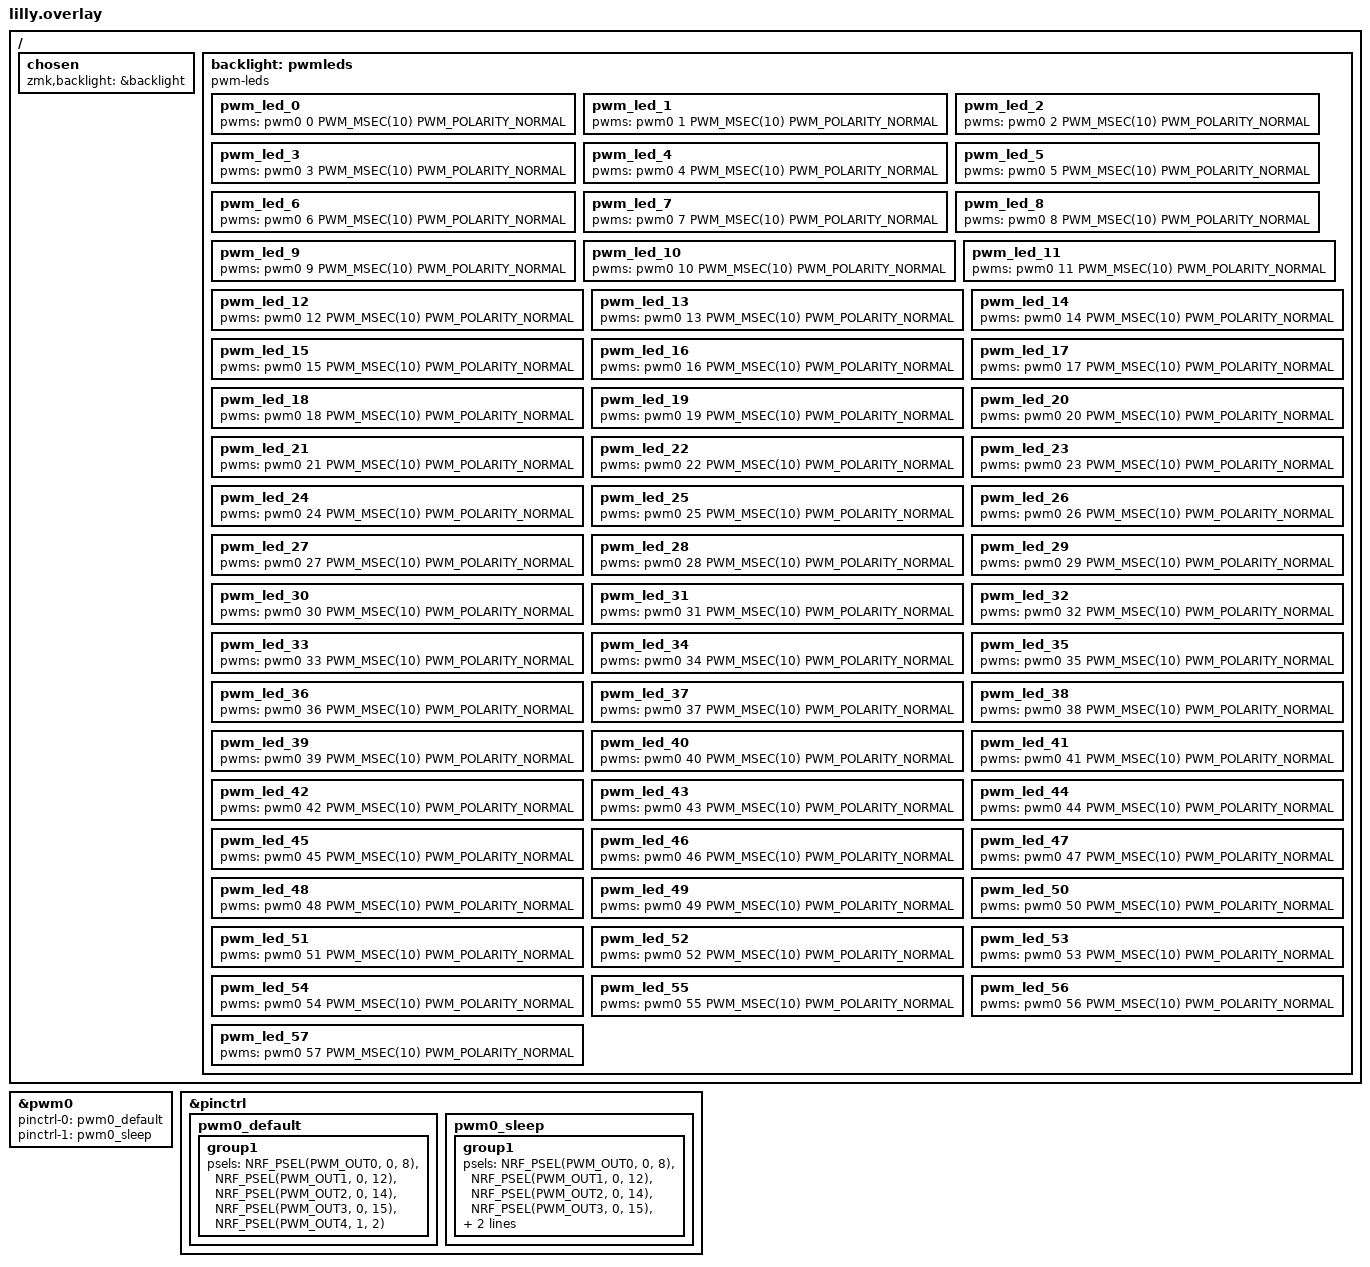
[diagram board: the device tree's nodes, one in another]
&pwm0 {
    status = "okay";
    pinctrl-0 = <&pwm0_default>;
    pinctrl-1 = <&pwm0_sleep>;
    pinctrl-names = "default", "sleep";
};

&pinctrl {
    pwm0_default: pwm0_default {
        group1 {
            psels = <NRF_PSEL(PWM_OUT0, 0, 8)>,  // PWM0 on P0.08 (First LED)
                    <NRF_PSEL(PWM_OUT1, 0, 12)>,  // PWM1 on P0.12 (Second LED)
                    <NRF_PSEL(PWM_OUT2, 0, 14)>,  // PWM2 on P0.14 (Third LED)
                    <NRF_PSEL(PWM_OUT3, 0, 15)>,  // PWM3 on P0.15 (Fourth LED)
                    <NRF_PSEL(PWM_OUT4, 1, 2)>;   // PWM4 on P1.02 (Fifth LED, and so on)
        };
    };

    pwm0_sleep: pwm0_sleep {
        group1 {
            psels = <NRF_PSEL(PWM_OUT0, 0, 8)>,  // Same pins in sleep mode
                    <NRF_PSEL(PWM_OUT1, 0, 12)>,
                    <NRF_PSEL(PWM_OUT2, 0, 14)>,
                    <NRF_PSEL(PWM_OUT3, 0, 15)>,
                    <NRF_PSEL(PWM_OUT4, 1, 2)>;
            low-power-enable;
        };
    };
};

/ {
    chosen {
        zmk,backlight = &backlight;
    };
};

/ {
    backlight: pwmleds {
        compatible = "pwm-leds";
    
        // Left side LEDs (pwm_led_0 to pwm_led_28)
        pwm_led_0: pwm_led_0 {
            pwms = <&pwm0 0 PWM_MSEC(10) PWM_POLARITY_NORMAL>;  // Left LED 1
        };
        pwm_led_1: pwm_led_1 {
            pwms = <&pwm0 1 PWM_MSEC(10) PWM_POLARITY_NORMAL>;  // Left LED 2
        };
        pwm_led_2: pwm_led_2 {
            pwms = <&pwm0 2 PWM_MSEC(10) PWM_POLARITY_NORMAL>;  // Left LED 3
        };
        pwm_led_3: pwm_led_3 {
            pwms = <&pwm0 3 PWM_MSEC(10) PWM_POLARITY_NORMAL>;  // Left LED 4
        };
        pwm_led_4: pwm_led_4 {
            pwms = <&pwm0 4 PWM_MSEC(10) PWM_POLARITY_NORMAL>;  // Left LED 5
        };
        pwm_led_5: pwm_led_5 {
            pwms = <&pwm0 5 PWM_MSEC(10) PWM_POLARITY_NORMAL>;  // Left LED 6
        };
        pwm_led_6: pwm_led_6 {
            pwms = <&pwm0 6 PWM_MSEC(10) PWM_POLARITY_NORMAL>;  // Left LED 7
        };
        pwm_led_7: pwm_led_7 {
            pwms = <&pwm0 7 PWM_MSEC(10) PWM_POLARITY_NORMAL>;  // Left LED 8
        };
        pwm_led_8: pwm_led_8 {
            pwms = <&pwm0 8 PWM_MSEC(10) PWM_POLARITY_NORMAL>;  // Left LED 9
        };
        pwm_led_9: pwm_led_9 {
            pwms = <&pwm0 9 PWM_MSEC(10) PWM_POLARITY_NORMAL>;  // Left LED 10
        };
        pwm_led_10: pwm_led_10 {
            pwms = <&pwm0 10 PWM_MSEC(10) PWM_POLARITY_NORMAL>;  // Left LED 11
        };
        pwm_led_11: pwm_led_11 {
            pwms = <&pwm0 11 PWM_MSEC(10) PWM_POLARITY_NORMAL>;  // Left LED 12
        };
        pwm_led_12: pwm_led_12 {
            pwms = <&pwm0 12 PWM_MSEC(10) PWM_POLARITY_NORMAL>;  // Left LED 13
        };
        pwm_led_13: pwm_led_13 {
            pwms = <&pwm0 13 PWM_MSEC(10) PWM_POLARITY_NORMAL>;  // Left LED 14
        };
        pwm_led_14: pwm_led_14 {
            pwms = <&pwm0 14 PWM_MSEC(10) PWM_POLARITY_NORMAL>;  // Left LED 15
        };
        pwm_led_15: pwm_led_15 {
            pwms = <&pwm0 15 PWM_MSEC(10) PWM_POLARITY_NORMAL>;  // Left LED 16
        };
        pwm_led_16: pwm_led_16 {
            pwms = <&pwm0 16 PWM_MSEC(10) PWM_POLARITY_NORMAL>;  // Left LED 17
        };
        pwm_led_17: pwm_led_17 {
            pwms = <&pwm0 17 PWM_MSEC(10) PWM_POLARITY_NORMAL>;  // Left LED 18
        };
        pwm_led_18: pwm_led_18 {
            pwms = <&pwm0 18 PWM_MSEC(10) PWM_POLARITY_NORMAL>;  // Left LED 19
        };
        pwm_led_19: pwm_led_19 {
            pwms = <&pwm0 19 PWM_MSEC(10) PWM_POLARITY_NORMAL>;  // Left LED 20
        };
        pwm_led_20: pwm_led_20 {
            pwms = <&pwm0 20 PWM_MSEC(10) PWM_POLARITY_NORMAL>;  // Left LED 21
        };
        pwm_led_21: pwm_led_21 {
            pwms = <&pwm0 21 PWM_MSEC(10) PWM_POLARITY_NORMAL>;  // Left LED 22
        };
        pwm_led_22: pwm_led_22 {
            pwms = <&pwm0 22 PWM_MSEC(10) PWM_POLARITY_NORMAL>;  // Left LED 23
        };
        pwm_led_23: pwm_led_23 {
            pwms = <&pwm0 23 PWM_MSEC(10) PWM_POLARITY_NORMAL>;  // Left LED 24
        };
        pwm_led_24: pwm_led_24 {
            pwms = <&pwm0 24 PWM_MSEC(10) PWM_POLARITY_NORMAL>;  // Left LED 25
        };
        pwm_led_25: pwm_led_25 {
            pwms = <&pwm0 25 PWM_MSEC(10) PWM_POLARITY_NORMAL>;  // Left LED 26
        };
        pwm_led_26: pwm_led_26 {
            pwms = <&pwm0 26 PWM_MSEC(10) PWM_POLARITY_NORMAL>;  // Left LED 27
        };
        pwm_led_27: pwm_led_27 {
            pwms = <&pwm0 27 PWM_MSEC(10) PWM_POLARITY_NORMAL>;  // Left LED 28
        };
        pwm_led_28: pwm_led_28 {
            pwms = <&pwm0 28 PWM_MSEC(10) PWM_POLARITY_NORMAL>;  // Left LED 29
        };
    
        // Right side LEDs (pwm_led_29 to pwm_led_57)
        pwm_led_29: pwm_led_29 {
            pwms = <&pwm0 29 PWM_MSEC(10) PWM_POLARITY_NORMAL>;  // Right LED 1
        };
        pwm_led_30: pwm_led_30 {
            pwms = <&pwm0 30 PWM_MSEC(10) PWM_POLARITY_NORMAL>;  // Right LED 2
        };
        pwm_led_31: pwm_led_31 {
            pwms = <&pwm0 31 PWM_MSEC(10) PWM_POLARITY_NORMAL>;  // Right LED 3
        };
        pwm_led_32: pwm_led_32 {
            pwms = <&pwm0 32 PWM_MSEC(10) PWM_POLARITY_NORMAL>;  // Right LED 4
        };
        pwm_led_33: pwm_led_33 {
            pwms = <&pwm0 33 PWM_MSEC(10) PWM_POLARITY_NORMAL>;  // Right LED 5
        };
        pwm_led_34: pwm_led_34 {
            pwms = <&pwm0 34 PWM_MSEC(10) PWM_POLARITY_NORMAL>;  // Right LED 6
        };
        pwm_led_35: pwm_led_35 {
            pwms = <&pwm0 35 PWM_MSEC(10) PWM_POLARITY_NORMAL>;  // Right LED 7
        };
        pwm_led_36: pwm_led_36 {
            pwms = <&pwm0 36 PWM_MSEC(10) PWM_POLARITY_NORMAL>;  // Right LED 8
        };
        pwm_led_37: pwm_led_37 {
            pwms = <&pwm0 37 PWM_MSEC(10) PWM_POLARITY_NORMAL>;  // Right LED 9
        };
        pwm_led_38: pwm_led_38 {
            pwms = <&pwm0 38 PWM_MSEC(10) PWM_POLARITY_NORMAL>;  // Right LED 10
        };
        pwm_led_39: pwm_led_39 {
            pwms = <&pwm0 39 PWM_MSEC(10) PWM_POLARITY_NORMAL>;  // Right LED 11
        };
        pwm_led_40: pwm_led_40 {
            pwms = <&pwm0 40 PWM_MSEC(10) PWM_POLARITY_NORMAL>;  // Right LED 12
        };
        pwm_led_41: pwm_led_41 {
            pwms = <&pwm0 41 PWM_MSEC(10) PWM_POLARITY_NORMAL>;  // Right LED 13
        };
        pwm_led_42: pwm_led_42 {
            pwms = <&pwm0 42 PWM_MSEC(10) PWM_POLARITY_NORMAL>;  // Right LED 14
        };
        pwm_led_43: pwm_led_43 {
            pwms = <&pwm0 43 PWM_MSEC(10) PWM_POLARITY_NORMAL>;  // Right LED 15
        };
        pwm_led_44: pwm_led_44 {
            pwms = <&pwm0 44 PWM_MSEC(10) PWM_POLARITY_NORMAL>;  // Right LED 16
        };
        pwm_led_45: pwm_led_45 {
            pwms = <&pwm0 45 PWM_MSEC(10) PWM_POLARITY_NORMAL>;  // Right LED 17
        };
        pwm_led_46: pwm_led_46 {
            pwms = <&pwm0 46 PWM_MSEC(10) PWM_POLARITY_NORMAL>;  // Right LED 18
        };
        pwm_led_47: pwm_led_47 {
            pwms = <&pwm0 47 PWM_MSEC(10) PWM_POLARITY_NORMAL>;  // Right LED 19
        };
        pwm_led_48: pwm_led_48 {
            pwms = <&pwm0 48 PWM_MSEC(10) PWM_POLARITY_NORMAL>;  // Right LED 20
        };
        pwm_led_49: pwm_led_49 {
            pwms = <&pwm0 49 PWM_MSEC(10) PWM_POLARITY_NORMAL>;  // Right LED 21
        };
        pwm_led_50: pwm_led_50 {
            pwms = <&pwm0 50 PWM_MSEC(10) PWM_POLARITY_NORMAL>;  // Right LED 22
        };
        pwm_led_51: pwm_led_51 {
            pwms = <&pwm0 51 PWM_MSEC(10) PWM_POLARITY_NORMAL>;  // Right LED 23
        };
        pwm_led_52: pwm_led_52 {
            pwms = <&pwm0 52 PWM_MSEC(10) PWM_POLARITY_NORMAL>;  // Right LED 24
        };
        pwm_led_53: pwm_led_53 {
            pwms = <&pwm0 53 PWM_MSEC(10) PWM_POLARITY_NORMAL>;  // Right LED 25
        };
        pwm_led_54: pwm_led_54 {
            pwms = <&pwm0 54 PWM_MSEC(10) PWM_POLARITY_NORMAL>;  // Right LED 26
        };
        pwm_led_55: pwm_led_55 {
            pwms = <&pwm0 55 PWM_MSEC(10) PWM_POLARITY_NORMAL>;  // Right LED 27
        };
        pwm_led_56: pwm_led_56 {
            pwms = <&pwm0 56 PWM_MSEC(10) PWM_POLARITY_NORMAL>;  // Right LED 28
        };
        pwm_led_57: pwm_led_57 {
            pwms = <&pwm0 57 PWM_MSEC(10) PWM_POLARITY_NORMAL>;  // Right LED 29
        };
    };
};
